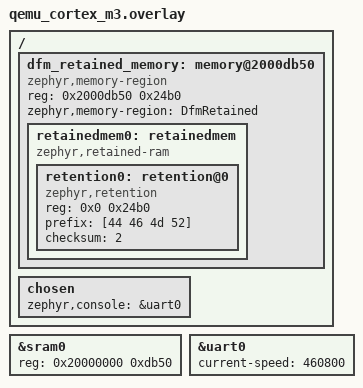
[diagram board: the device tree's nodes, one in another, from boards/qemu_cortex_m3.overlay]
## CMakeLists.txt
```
# SPDX-License-Identifier: Apache-2.0

cmake_minimum_required(VERSION 3.20.0)

set(DEMO_PERCEPIO_SOURCE "local" CACHE STRING "Percepio sources: local or upstream")
set_property(CACHE DEMO_PERCEPIO_SOURCE PROPERTY STRINGS local upstream)
if(DEMO_PERCEPIO_SOURCE STREQUAL "local")
  foreach(library DFM TraceRecorder)
    if(NOT EXISTS "${CMAKE_CURRENT_LIST_DIR}/../PercepioLibs/${library}/kernelports/Zephyr/Kconfig")
      message(FATAL_ERROR
        "Local ${library} sources are missing from ../PercepioLibs. "
        "Check out the complete demo repository or select -DDEMO_PERCEPIO_SOURCE=upstream.")
    endif()
  endforeach()
  list(APPEND EXTRA_ZEPHYR_MODULES "${CMAKE_CURRENT_LIST_DIR}/modules/percepio")
elseif(NOT DEMO_PERCEPIO_SOURCE STREQUAL "upstream")
  message(FATAL_ERROR "DEMO_PERCEPIO_SOURCE must be local or upstream")
endif()
message(STATUS "Percepio source: ${DEMO_PERCEPIO_SOURCE}")

find_package(Zephyr REQUIRED HINTS $ENV{ZEPHYR_BASE})
project(zephyr)

# Keep repository source paths relative to the shipped debug bundle.
get_filename_component(DEMO_REPO_ROOT "${CMAKE_CURRENT_SOURCE_DIR}/.." ABSOLUTE)
zephyr_compile_options(
  "-fdebug-prefix-map=${DEMO_REPO_ROOT}=src"
  "-fdebug-prefix-map=${ZEPHYR_BASE}/kernel=."  
)

# Logged terminal targets for the documented QEMU board; other boards keep
# Zephyr's native run/debug/flash targets.
include(cmake/qemu-cortex-m3.cmake)

if(DEFINED DEBUG_PRINTF)
  zephyr_compile_definitions(DEBUG_PRINTF=${DEBUG_PRINTF})
endif()
if(DEFINED SAME_PRIO)
  zephyr_compile_definitions(SAME_PRIO)
endif()
if(DEFINED STATIC_OBJS)
  zephyr_compile_definitions(STATIC_OBJS)
endif()
if(DEFINED FORKS)
  zephyr_compile_definitions(FORKS=${FORKS})
endif()

target_sources(app PRIVATE  
  src/main.c
  src/qemu_reboot_workaround.c
  ${CMAKE_CURRENT_LIST_DIR}/../UsageExamples/demo_app.c
  ${CMAKE_CURRENT_LIST_DIR}/../UsageExamples/01_tracerecorder_kernel_tracing.c
  ${CMAKE_CURRENT_LIST_DIR}/../UsageExamples/02_tracerecorder_data_logging.c
  ${CMAKE_CURRENT_LIST_DIR}/../UsageExamples/03_tracerecorder_state_logging.c
  ${CMAKE_CURRENT_LIST_DIR}/../UsageExamples/10_dfm_crash_alert.c
  ${CMAKE_CURRENT_LIST_DIR}/../UsageExamples/11_dfm_custom_alert.c
  ${CMAKE_CURRENT_LIST_DIR}/../UsageExamples/12_dfm_stack_corruption_alert.c
  ${CMAKE_CURRENT_LIST_DIR}/../UsageExamples/13_dfm_stopwatch_alert.c
  ${CMAKE_CURRENT_LIST_DIR}/../UsageExamples/14_dfm_taskmonitor_alert.c  
  ${CMAKE_CURRENT_LIST_DIR}/../UsageExamples/15_dfm_custom_payload_alert.c
  )

target_include_directories(app PRIVATE
  ${CMAKE_CURRENT_LIST_DIR}/src
  ${CMAKE_CURRENT_LIST_DIR}/../UsageExamples
 )
```

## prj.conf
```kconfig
#############################################################################
# Percepio Tracealyzer and Detect - Reference Configuration for Zephyr
#############################################################################

# ---------------------------------------------------------------------------
# Percepio TraceRecorder - Required/Recommended Settings 
# for Detect and Tracealyzer snapshots
# ---------------------------------------------------------------------------

# Master switch for Zephyr tracing support 
CONFIG_TRACING=y

# Enable Percepio TraceRecorder
CONFIG_PERCEPIO_TRACERECORDER=y

# How to store the trace data (ring-buffer in target RAM)
CONFIG_PERCEPIO_TRC_CFG_STREAM_PORT_RINGBUFFER=y


# ---------------------------------------------------------------------------
# Percepio Detect - Required/Recommended Settings
# ---------------------------------------------------------------------------

# Master switch that enables the DFM library (Percepio Detect API)
CONFIG_PERCEPIO_DFM=y

# The device software version provided in the DFM alert metadata
CONFIG_PERCEPIO_DFM_CFG_FIRMWARE_VERSION="zephyr-demo-v1.0"

# Increase the size of the Description field in the alerts, if needed.
# Default is 64. The server allows for up to 100 chars here.
CONFIG_PERCEPIO_DFM_CFG_DESCRIPTION_MAX_LEN=96

# Select the Detect transport ("Serial" option). 
CONFIG_PERCEPIO_DFM_CFG_CLOUDPORT_SERIAL=y

# Required for DFM_TRAP() to restart the device
CONFIG_REBOOT=y

# Enables the DFM TaskMonitor for CPU load anomaly detection
CONFIG_PERCEPIO_TRC_CFG_ENABLE_TASK_MONITOR=y

# For DFM TaskMonitor - the maximum number of threads that can be monitored.
# Should match or exceed the number of threads registered via xDfmTaskMonitorRegister().
CONFIG_PERCEPIO_TRC_CFG_TASK_MONITOR_MAX_TASKS=2

# Needed by the DFM TaskMonitor
CONFIG_THREAD_LOCAL_STORAGE=y

# Required by DFM_TRAP() on Arm Cortex-M devices to run in exception
# handler context, allowing it to emulate a fault exception and trigger a core dump.
CONFIG_IRQ_OFFLOAD=y

# Required by DFM_TRAP() on Arm Cortex-M devices. Zephyr's irq_offload() API is
# part of the Zephyr test infrastructure and therefore requires CONFIG_TEST.
#
# Preliminary analysis indicates that CONFIG_TEST has the following
# side effects, depending on the Zephyr version and target:
# - Enables thread naming support via CONFIG_THREAD_NAME.
# - Enables Zephyr test logging defaults, which may enable logging.
# - May enable hardware stack protection when supported by the target.
# - Enables Cortex-M-specific test configuration via CONFIG_TEST_ARM_CORTEX_M,
#   which may affect stack sizing, null-pointer detection, and exception
#   routing on some Arm targets, including Secure Armv8-M builds.
CONFIG_TEST=y


# ---------------------------------------------------------------------------
# Core Dumps
# ---------------------------------------------------------------------------

# Enable the DFM core dump support
CONFIG_PERCEPIO_DFM_CFG_ENABLE_COREDUMPS=y

# Enable core dump support in Zephyr
CONFIG_DEBUG_COREDUMP=y

# Select the core dump backend "other" (DFM trcKernelPort.c)
CONFIG_DEBUG_COREDUMP_BACKEND_OTHER=y

# Use the minimal core dump format (the only supported option in Detect 2026.1)
CONFIG_DEBUG_COREDUMP_MEMORY_DUMP_MIN=y

# Preserve r4-r11 in the exception frame. In particular, GCC uses r7 as the
# frame pointer at -O0, so this is required for correct locals and unwinding.
CONFIG_EXTRA_EXCEPTION_INFO=y


#############################################################################
# Demo-specific Configuration (Optional)
#############################################################################

# Zephyr: Default prioriy levels are 15, but make it explicit.
CONFIG_NUM_PREEMPT_PRIORITIES=15

# Zephyr: The demo uses sub-10 ms sleeps, so increase the tick resolution.
CONFIG_SYS_CLOCK_TICKS_PER_SEC=1000

# TraceRecorder: Enable internal error handling (Recommended)
CONFIG_PERCEPIO_TRC_CFG_USE_TRACE_ASSERT=y

# TraceRecorder: Ensure sufficient stack
CONFIG_PERCEPIO_TRC_CFG_CTRL_TASK_STACK_SIZE=1024

# TraceRecorder: Size of trace buffer
CONFIG_PERCEPIO_TRC_CFG_STREAM_PORT_RINGBUFFER_SIZE=4096

# TraceRecorder: Exclude less important events (Recommended)
CONFIG_TRACING_POLLING=n
CONFIG_TRACING_SYSCALL=n
CONFIG_PERCEPIO_TRC_CFG_INCLUDE_BUSY_WAIT=n
CONFIG_PERCEPIO_TRC_CFG_INCLUDE_YIELD=n
CONFIG_PERCEPIO_TRC_CFG_INCLUDE_SCHED_LOCK=n

# TraceRecorder: Enables periodic stack usage monitoring
CONFIG_PERCEPIO_TRC_CFG_ENABLE_STACK_MONITOR=y

# TraceRecorder: Trace control task setup (not really needed here, except for stack monitoring)
CONFIG_PERCEPIO_TRC_CFG_CTRL_TASK_PRIORITY=14
CONFIG_PERCEPIO_TRC_CFG_CTRL_TASK_DELAY=250

# Ensures core dumps are transmitted directly
CONFIG_PERCEPIO_DFM_CFG_COREDUMP_SEND=y

# Reduce dump size by including only the top part of the faulting thread's stack.
# The upper limit is set by CONFIG_DEBUG_COREDUMP_THREAD_STACK_TOP_LIMIT.
# CONFIG_DEBUG_COREDUMP_THREAD_STACK_TOP=y

# Maximum number of stack bytes included in the core dump.
# CONFIG_DEBUG_COREDUMP_THREAD_STACK_TOP_LIMIT=128

# Enable this to use Arm DWT-based timestamping. This typically provides
# higher timestamp resolution than the default timebase, but is specific
# to Cortex-M devices with DWT support (e.g. Cortex-M3/M4/M7 and many M33
# implementations). Not supported by the QEMU targets used by this demo.
CONFIG_CORTEX_M_DWT=n

# ---------------------------------------------------------------------------
# Retained Memory
# ---------------------------------------------------------------------------
# "Retained Memory" means that the DFM alert data is initially
# stored in RAM that survives a restart.
# DFM can be configured to use Zephyr Retained Memory support.
# This way, the system can be restarted to recover from a fault 
# without losing the alert data and transmit it later.
# Add the matching boards/*_retained.overlay to reserve the DFM storage region.

# CONFIG_PERCEPIO_DFM_CFG_COREDUMP_RETAIN=n
# CONFIG_RETENTION=n
# CONFIG_RETAINED_MEM=n
# CONFIG_PERCEPIO_DFM_CFG_RETAINED_MEMORY=y
# CONFIG_PERCEPIO_DFM_CFG_COREDUMP_RETAIN=y

# ---------------------------------------------------------------------------
# DFM Diagnostics for Integration Verification and Debugging
# ---------------------------------------------------------------------------

# Enables diagnostic printk statements in DFM.
CONFIG_PERCEPIO_DFM_CFG_ENABLE_DEBUG_PRINT=y

# Enable thread awareness for debugging tools supporting it.
CONFIG_DEBUG_THREAD_INFO=y

# Disables compiler optimizations
CONFIG_NO_OPTIMIZATIONS=y
#CONFIG_DEBUG_OPTIMIZATIONS=y

# ---------------------------------------------------------------------------
# Stack Corruption Detection (for the stack corruption demo)
# ---------------------------------------------------------------------------

# For stack checking / stack corruption detection. qemu_cortex_m3 has no
# entropy device, so use Zephyr's deterministic test RNG to seed canaries.
CONFIG_TEST_RANDOM_GENERATOR=y
CONFIG_STACK_CANARIES_STRONG=y
CONFIG_STACK_SENTINEL=y
```

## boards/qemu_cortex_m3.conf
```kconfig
# QEMU-specific timing mode. Physical boards use their native timer.
CONFIG_QEMU_ICOUNT=y
CONFIG_QEMU_ICOUNT_SLEEP=y
# Keep the supplied native QEMU F5 configuration in sync with this value.
CONFIG_QEMU_ICOUNT_SHIFT=6
```

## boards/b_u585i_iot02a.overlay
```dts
/* Run the console at 4 x the board default. */

&usart1 {
	current-speed = <460800>;
};
```

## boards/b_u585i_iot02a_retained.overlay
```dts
/* Reserve the upper 9,392 bytes of SRAM for one full DFM retained alert plus
 * 2.5% user-data margin.
 * This suffix overlay is not loaded automatically. Add it with:
 *   -DEXTRA_DTC_OVERLAY_FILE=boards/b_u585i_iot02a_retained.overlay
 * when CONFIG_PERCEPIO_DFM_CFG_RETAINED_MEMORY=y. Do not combine it with
 * another overlay that reserves the same upper SRAM range.
 */

/ {
	dfm_retained_memory: memory@200bdb50 {
		compatible = "zephyr,memory-region", "mmio-sram";
		reg = <0x200bdb50 0x24b0>;
		ranges = <0x0 0x200bdb50 0x24b0>;
		zephyr,memory-region = "DfmRetained";
		status = "okay";
		#address-cells = <1>;
		#size-cells = <1>;

		retainedmem0: retainedmem {
			compatible = "zephyr,retained-ram";
			status = "okay";
			ranges;
			#address-cells = <1>;
			#size-cells = <1>;

			retention0: retention@0 {
				compatible = "zephyr,retention";
				status = "okay";
				reg = <0x0 0x24b0>;
				prefix = [44 46 4d 52];
				checksum = <0>;
			};
		};
	};
};

&sram0 {
	reg = <0x20000000 0xbdb50>;
};
```

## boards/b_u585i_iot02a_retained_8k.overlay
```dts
/* Reserve the upper 8 KiB of SRAM for the small DFM retained test variant.
 * This intentionally undersized suffix overlay is not loaded automatically.
 * The m3_retained_8k test selects it with:
 *   -DEXTRA_DTC_OVERLAY_FILE=boards/b_u585i_iot02a_retained_8k.overlay
 * Do not combine it with another overlay that reserves the same SRAM range.
 */

/ {
	dfm_retained_memory: memory@200be000 {
		compatible = "zephyr,memory-region", "mmio-sram";
		reg = <0x200be000 0x2000>;
		ranges = <0x0 0x200be000 0x2000>;
		zephyr,memory-region = "DfmRetained";
		status = "okay";
		#address-cells = <1>;
		#size-cells = <1>;

		retainedmem0: retainedmem {
			compatible = "zephyr,retained-ram";
			status = "okay";
			ranges;
			#address-cells = <1>;
			#size-cells = <1>;

			retention0: retention@0 {
				compatible = "zephyr,retention";
				status = "okay";
				reg = <0x0 0x2000>;
				prefix = [44 46 4d 52];
				checksum = <0>;
			};
		};
	};
};

&sram0 {
	reg = <0x20000000 0xbe000>;
};
```

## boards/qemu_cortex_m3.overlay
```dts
/ {
	dfm_retained_memory: memory@2000db50 {
		compatible = "zephyr,memory-region", "mmio-sram";
		reg = <0x2000db50 0x24b0>;
		ranges = <0x0 0x2000db50 0x24b0>;
		zephyr,memory-region = "DfmRetained";
		status = "okay";
		#address-cells = <1>;
		#size-cells = <1>;

		retainedmem0: retainedmem {
			compatible = "zephyr,retained-ram";
			status = "okay";
			ranges;
			#address-cells = <1>;
			#size-cells = <1>;

			retention0: retention@0 {
				compatible = "zephyr,retention";
				status = "okay";
				reg = <0x0 0x24b0>;
				prefix = [44 46 4d 52];
				checksum = <2>;
			};
		};
	};

    chosen {
        zephyr,console = &uart0;
    };
};

&sram0 {
	reg = <0x20000000 0xdb50>;
};

&uart0 {
    current-speed = <460800>;
    status = "okay";
};
```

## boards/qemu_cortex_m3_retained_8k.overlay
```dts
/* Reserve the upper 8 KiB of SRAM for the small DFM retained test variant.
 * This intentionally undersized suffix overlay is not loaded automatically.
 * The m3_retained_8k test selects it with:
 *   -DEXTRA_DTC_OVERLAY_FILE=boards/qemu_cortex_m3_retained_8k.overlay
 * Do not combine it with another overlay that reserves the same SRAM range.
 */

/ {
	dfm_retained_memory: memory@2000e000 {
		compatible = "zephyr,memory-region", "mmio-sram";
		reg = <0x2000e000 0x2000>;
		ranges = <0x0 0x2000e000 0x2000>;
		zephyr,memory-region = "DfmRetained";
		status = "okay";
		#address-cells = <1>;
		#size-cells = <1>;

		retainedmem0: retainedmem {
			compatible = "zephyr,retained-ram";
			status = "okay";
			ranges;
			#address-cells = <1>;
			#size-cells = <1>;

			retention0: retention@0 {
				compatible = "zephyr,retention";
				status = "okay";
				reg = <0x0 0x2000>;
				prefix = [44 46 4d 52];
				checksum = <0>;
			};
		};
	};
};

&sram0 {
	reg = <0x20000000 0xe000>;
};
```

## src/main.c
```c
#include "zephyr/linker/section_tags.h"
#include <zephyr/kernel.h>
#include <zephyr/sys/__assert.h>
#include <zephyr/fatal.h>
#include <zephyr/sys/reboot.h>

#if defined(CONFIG_PERCEPIO_DFM_CFG_RETAINED_MEMORY)
#include <dfm.h>
#endif

#if defined(CONFIG_STDOUT_CONSOLE)
#include <stdio.h>
#else
#include <zephyr/sys/printk.h>
#endif

#include "demo_app.h"

/*
  
  NOTE: This demo application of Percepio Detect for Zephyr is a work-in-progress,
  and assumes updated versions of the Percepio modules TraceRecorder and DFM found in "modules-staging".*/  

int main(void){

#if CONFIG_TIMESLICING
	k_sched_time_slice_set(5000, 0);
#endif

	/* Give the host time to reopen the USB/UART console after flashing or a
	 * target reset before emitting the demo output.
	 */
	k_sleep(K_SECONDS(1));

#if defined(CONFIG_PERCEPIO_DFM_CFG_RETAINED_MEMORY)
	if (xDfmRetainedMemoryPortHasData())
	{
		if (xDfmAlertSendAll() != DFM_SUCCESS) {
			printk("Failed to send retained DFM alerts\n");
			return -1;
		}
	}
#endif

	printk("Starting Percepio Detect demo\n");
	demo_app();

	return 0;
}


__noinit unsigned int last_demo_counter;

unsigned int selectNextDemo(void)
{	
  if (last_demo_counter >= NUMBER_OF_DEMOS) 
	{	
    last_demo_counter = 0;		
	}
	  	
	return last_demo_counter++;
}


/* Called by Zephyr as the final step in the fault handling, after DFM has
  stored its' alert with TraceRecorder diagnostics etc. In this demo we just
  restart at this point, but you may use this to add custom fault handling
  actions that execute after DFM. */

void k_sys_fatal_error_handler(unsigned int reason, const struct arch_esf *esf)
{	
    ARG_UNUSED(esf);

    ARG_UNUSED(reason);

    printk("Fatal error, rebooting...\n");
    k_busy_wait(1000);   /* Let final UART chars drain before rebooting. */

    sys_reboot(SYS_REBOOT_COLD);

    CODE_UNREACHABLE;
}
```

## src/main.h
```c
/* Define to prevent recursive inclusion -------------------------------------*/
#ifndef __MAIN_H
#define __MAIN_H

#include "osal.h"

/* Not sure which are needed */
#include <stdio.h>
#include <stdint.h>
#include <stdlib.h>
#include <string.h>

/* Important */
/*
#ifndef LNBR
#define LNBR "\n"
#endif
*/

#define DEMO_PRINTF(fmt, ...)                     \
  do {                                                \
    xTraceConsoleChannelPrintF((fmt), ##__VA_ARGS__); \
  	printk((fmt), ##__VA_ARGS__);                     \
    printk(LNBR); \
  } while (0)

#endif /* __MAIN_H */
```

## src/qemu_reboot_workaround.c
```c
/*
 * Work around the qemu_cortex_m3 software-reboot path when building with
 * -O0/-Og and CONFIG_INIT_STACKS=y.
 *
 * The LM3S6965 QEMU model cannot reset through SYSRESETREQ. Zephyr therefore
 * leaves Handler mode through a synthetic exception frame and enters the
 * reset code with PSP temporarily located inside z_interrupt_stacks. The
 * default weak arch_early_memset() gets a stack frame at -O0/-Og; clearing
 * z_interrupt_stacks then overwrites that frame and returns to 0xAAAAAAAA.
 *
 * This strong, stackless implementation replaces the weak default only for
 * the affected QEMU target and debug optimization modes.
 */

#include <stddef.h>

#if defined(CONFIG_SOC_TI_LM3S6965_QEMU) && \
	(defined(CONFIG_NO_OPTIMIZATIONS) || defined(CONFIG_DEBUG_OPTIMIZATIONS))

__attribute__((naked, no_stack_protector))
void arch_early_memset(void *dst __attribute__((unused)),
		       int value __attribute__((unused)),
		       size_t size __attribute__((unused)))
{
	__asm__ volatile(
		"cmp r2, #0\n"
		"beq 2f\n"
		"1:\n"
		"strb r1, [r0]\n"
		"adds r0, r0, #1\n"
		"subs r2, r2, #1\n"
		"bne 1b\n"
		"2:\n"
		"bx lr\n");
}

#endif
```
